AUTOSAR XML (schema 00050)
package /MICROSAR/ComM_swc
  mode declaration group ComMMode: initial-mode=COMM_NO_COMMUNICATION
    mode COMM_NO_COMMUNICATION
    mode COMM_SILENT_COMMUNICATION
    mode COMM_FULL_COMMUNICATION
  data type mapping set ComMMode_DataTypeMappingSet: mode-request-type-map{implementation-data-type=ComM_ModeType, mode-group=ComMMode}  # Data Mapping for the Mode Declaration Group ComMMode.
package /MICROSAR/ComM_swc/DataTypes
  4 x impl type, all with category=TYPE_REFERENCE:
    ComM_ModeType: compu {0=COMM_NO_COMMUNICATION, 1=COMM_SILENT_COMMUNICATION, 2=COMM_FULL_COMMUNICATION}, range raw 0..3, implementation-data-type=uint8
    ComM_InhibitionStatusType: range raw 0..255, implementation-data-type=uint8
    ComM_UserHandleType: range raw 0..65535, implementation-data-type=uint16
    NetworkHandleType: range raw 0..255, implementation-data-type=uint8, type-emitter=ComM
package /MICROSAR/ComM_swc/Interfaces
  4 x client server interface, all with is-service=true, service-kind=COM-MANAGER:
    ComM_UserRequest
      4 x operation:
        RequestComMode: possible-error=[ComM_UserRequest/E_NOT_OK, E_MODE_LIMITATION]
          arg ComMode: type=ComM_ModeType, direction=IN
        GetCurrentComMode: possible-error=ComM_UserRequest/E_NOT_OK
          arg ComMode: type=ComM_ModeType, direction=OUT
        GetMaxComMode: possible-error=ComM_UserRequest/E_NOT_OK
          arg ComMode: type=ComM_ModeType, direction=OUT
        GetRequestedComMode: possible-error=ComM_UserRequest/E_NOT_OK
          arg ComMode: type=ComM_ModeType, direction=OUT
      4 x error:
        E_NOT_OK: error-code=1
        E_MODE_LIMITATION: error-code=2
        E_MULTIPLE_PNC_ASSIGNED: error-code=3
        E_NO_PNC_ASSIGNED: error-code=4
    ComM_ECUModeLimitation
      4 x operation, all with possible-error=ComM_ECUModeLimitation/E_NOT_OK:
        LimitECUToNoComMode
          arg Status: type=boolean, direction=IN
        ReadInhibitCounter
          arg CounterValue: type=uint16, direction=OUT
        ResetInhibitCounter
        SetECUGroupClassification
          arg Status: type=ComM_InhibitionStatusType, direction=IN
      error E_NOT_OK: error-code=1
    ComM_ChannelWakeUp
      operation PreventWakeUp: possible-error=ComM_ChannelWakeUp/E_NOT_OK
        arg Status: type=boolean, direction=IN
      operation GetInhibitionStatus: possible-error=ComM_ChannelWakeUp/E_NOT_OK
        arg Status: type=ComM_InhibitionStatusType, direction=OUT
      error E_NOT_OK: error-code=1
    ComM_ChannelLimitation
      operation LimitChannelToNoComMode: possible-error=ComM_ChannelLimitation/E_NOT_OK
        arg Status: type=boolean, direction=IN
      operation GetInhibitionStatus: possible-error=ComM_ChannelLimitation/E_NOT_OK
        arg Status: type=ComM_InhibitionStatusType, direction=OUT
      error E_NOT_OK: error-code=1
  mode switch interface ComM_CurrentMode: is-service=true, service-kind=COM-MANAGER
    mode group currentMode: type=ComMMode
package /MICROSAR/ComM_swc/ComponentTypes
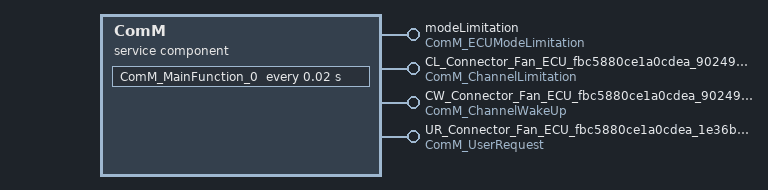
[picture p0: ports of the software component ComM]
  service sw component type ComM: category=SERVICE_COMPONENT
    4 x provide port:
      modeLimitation: provided-interface=ComM_ECUModeLimitation
      CL_Connector_Fan_ECU_fbc5880ce1a0cdea_90249745: provided-interface=ComM_ChannelLimitation
      CW_Connector_Fan_ECU_fbc5880ce1a0cdea_90249745: provided-interface=ComM_ChannelWakeUp
      UR_Connector_Fan_ECU_fbc5880ce1a0cdea_1e36b570: provided-interface=ComM_UserRequest
    behavior ComMInternalBehavior: data-type-mapping=ComMMode_DataTypeMappingSet, handle-termination-and-restart=NO-SUPPORT, included-data-type-set=data-type=[ComM_ModeType, ComM_InhibitionStatusType, ComM_UserHandleType, NetworkHandleType]
      timing event Timer_ComM_MainFunction_0: start-on-event=ComM_MainFunction_0, period=0.02
      12 x operation invoked event:
        OpEventLimitECUToNoComMode_LimitECUToNoComMode_modeLimitation: start-on-event=LimitECUToNoComMode, operation=modeLimitation.LimitECUToNoComMode
        OpEventReadInhibitCounter_ReadInhibitCounter_modeLimitation: start-on-event=ReadInhibitCounter, operation=modeLimitation.ReadInhibitCounter
        OpEventResetInhibitCounter_ResetInhibitCounter_modeLimitation: start-on-event=ResetInhibitCounter, operation=modeLimitation.ResetInhibitCounter
        OpEventSetECUGroupClassification_SetECUGroupClassification_modeLimitation: start-on-event=SetECUGroupClassification, operation=modeLimitation.SetECUGroupClassification
        OpEventGetInhibitionStatus_GetInhibitionStatus_CL_Connector_Fan_ECU_fbc5880ce1a0cdea_90249745: start-on-event=GetInhibitionStatus, operation=CL_Connector_Fan_ECU_fbc5880ce1a0cdea_90249745.GetInhibitionStatus
        OpEventGetInhibitionStatus_GetInhibitionStatus_CW_Connector_Fan_ECU_fbc5880ce1a0cdea_90249745: start-on-event=GetInhibitionStatus, operation=CW_Connector_Fan_ECU_fbc5880ce1a0cdea_90249745.GetInhibitionStatus
        OpEventLimitChannelToNoComMode_LimitChannelToNoComMode_CL_Connector_Fan_ECU_fbc5880ce1a0cdea_90249745: start-on-event=LimitChannelToNoComMode, operation=CL_Connector_Fan_ECU_fbc5880ce1a0cdea_90249745.LimitChannelToNoComMode
        OpEventPreventWakeUp_PreventWakeUp_CW_Connector_Fan_ECU_fbc5880ce1a0cdea_90249745: start-on-event=PreventWakeUp, operation=CW_Connector_Fan_ECU_fbc5880ce1a0cdea_90249745.PreventWakeUp
        OpEventRequestComMode_RequestComMode_UR_Connector_Fan_ECU_fbc5880ce1a0cdea_1e36b570: start-on-event=RequestComMode, operation=UR_Connector_Fan_ECU_fbc5880ce1a0cdea_1e36b570.RequestComMode
        OpEventGetCurrentComMode_GetCurrentComMode_UR_Connector_Fan_ECU_fbc5880ce1a0cdea_1e36b570: start-on-event=GetCurrentComMode, operation=UR_Connector_Fan_ECU_fbc5880ce1a0cdea_1e36b570.GetCurrentComMode
        OpEventGetMaxComMode_GetMaxComMode_UR_Connector_Fan_ECU_fbc5880ce1a0cdea_1e36b570: start-on-event=GetMaxComMode, operation=UR_Connector_Fan_ECU_fbc5880ce1a0cdea_1e36b570.GetMaxComMode
        OpEventGetRequestedComMode_GetRequestedComMode_UR_Connector_Fan_ECU_fbc5880ce1a0cdea_1e36b570: start-on-event=GetRequestedComMode, operation=UR_Connector_Fan_ECU_fbc5880ce1a0cdea_1e36b570.GetRequestedComMode
      port-api-options:
        enable-take-address=true, indirect-api=false, port=modeLimitation
        {enable-take-address=true, indirect-api=false, port-defined-argument-value{value=0, value-type=NetworkHandleType}, port=CL_Connector_Fan_ECU_fbc5880ce1a0cdea_90249745}
        {enable-take-address=true, indirect-api=false, port-defined-argument-value{value=0, value-type=NetworkHandleType}, port=CW_Connector_Fan_ECU_fbc5880ce1a0cdea_90249745}
        {enable-take-address=true, indirect-api=false, port-defined-argument-value{value=0, value-type=ComM_UserHandleType}, port=UR_Connector_Fan_ECU_fbc5880ce1a0cdea_1e36b570}
      12 x runnable, all with can-be-invoked-concurrently=true:
        ComM_MainFunction_0
        GetInhibitionStatus: symbol=ComM_GetInhibitionStatus
        LimitECUToNoComMode: symbol=ComM_LimitECUToNoComMode
        ReadInhibitCounter: symbol=ComM_ReadInhibitCounter
        ResetInhibitCounter: symbol=ComM_ResetInhibitCounter
        SetECUGroupClassification: symbol=ComM_SetECUGroupClassification
        LimitChannelToNoComMode: symbol=ComM_LimitChannelToNoComMode
        PreventWakeUp: symbol=ComM_PreventWakeUp
        RequestComMode: symbol=ComM_RequestComMode
        GetCurrentComMode: symbol=ComM_GetCurrentComMode
        GetMaxComMode: symbol=ComM_GetMaxComMode
        GetRequestedComMode: symbol=ComM_GetRequestedComMode
  swc implementation ComMImplementation: programming-language=C, behavior=ComMInternalBehavior
    resource consumption ComMResourceConsumption
      5 x memory section:
        ComM_START_SEC_CODE: sw-addrmethod=CODE, symbol=CODE
        ComM_START_SEC_CONST_UNSPECIFIED: alignment=UNSPECIFIED, sw-addrmethod=CONST, symbol=CONST_UNSPECIFIED
        ComM_START_SEC_VAR_NOINIT_UNSPECIFIED: alignment=UNSPECIFIED, sw-addrmethod=VAR_NO_INIT, symbol=VAR_NOINIT_UNSPECIFIED
        ComM_START_SEC_VAR_INIT_UNSPECIFIED: alignment=UNSPECIFIED, sw-addrmethod=VAR_INIT, symbol=VAR_INIT_UNSPECIFIED
        ComM_START_SEC_VAR_ZERO_INIT_UNSPECIFIED: alignment=UNSPECIFIED, sw-addrmethod=VAR_CLEARED, symbol=VAR_ZERO_INIT_UNSPECIFIED
